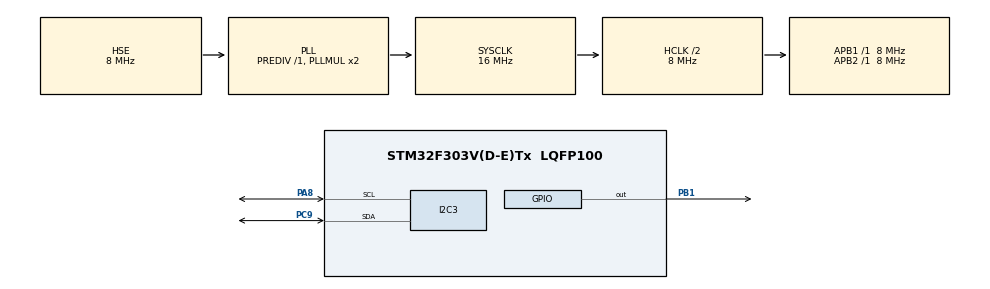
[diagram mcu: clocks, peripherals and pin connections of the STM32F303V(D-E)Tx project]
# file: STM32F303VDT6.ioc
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Mcu.Family=STM32F3
Mcu.Name=STM32F303V(D-E)Tx
Mcu.Package=LQFP100
NVIC.PriorityGroup=NVIC_PRIORITYGROUP_4
NVIC.TIM6_DAC_IRQn=true\:0\:0\:false\:false\:true\:true
NVIC.TIM7_IRQn=true\:0\:0\:false\:false\:true\:true
PA8.Mode=I2C
PA8.Signal=I2C3_SCL
PB1.Signal=GPIO_Output
PC9.Mode=I2C
PC9.Signal=I2C3_SDA
PF0-OSC_IN.Mode=HSE-External-Oscillator
PF0-OSC_IN.Signal=RCC_OSC_IN
PF1-OSC_OUT.Mode=HSE-External-Oscillator
PF1-OSC_OUT.Signal=RCC_OSC_OUT
ProjectManager.HeapSize=0x200
ProjectManager.StackSize=0x400
ProjectManager.TargetToolchain=TrueSTUDIO
RCC.AHBCLKDivider=RCC_SYSCLK_DIV2
RCC.AHBFreq_Value=8000000
RCC.APB1Freq_Value=8000000
RCC.APB1TimFreq_Value=8000000
RCC.APB2Freq_Value=8000000
RCC.APB2TimFreq_Value=8000000
RCC.CortexFreq_Value=8000000
RCC.HCLKFreq_Value=8000000
RCC.HSE_VALUE=8000000
RCC.HSI_VALUE=8000000
RCC.PLLSourceVirtual=RCC_PLLSOURCE_HSE
RCC.SYSCLKFreq_VALUE=16000000
RCC.SYSCLKSourceVirtual=RCC_SYSCLKSOURCE_PLLCLK
RCC.USBFreq_Value=16000000
TIM6.Period=500
TIM6.Prescaler=8000
TIM6.TIM_MasterOutputTrigger=TIM_TRGO_UPDATE
TIM7.Period=2000
TIM7.Prescaler=8000
VP_TIM6_VS_ClockSourceINT.Mode=Enable_Timer
VP_TIM7_VS_ClockSourceINT.Mode=Enable_Timer
board=STM32F303VDT6

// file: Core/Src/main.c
/**
  ******************************************************************************
  * @file           : main.c
  * @brief          : Main program body
  ******************************************************************************
  ** This notice applies to any and all portions of this file
  * that are not between comment pairs USER CODE BEGIN and
  * USER CODE END. Other portions of this file, whether
  * inserted by the user or by software development tools
  * are owned by their respective copyright owners.
  *
  * COPYRIGHT(c) 2018 STMicroelectronics
  *
  * Redistribution and use in source and binary forms, with or without modification,
  * are permitted provided that the following conditions are met:
  *   1. Redistributions of source code must retain the above copyright notice,
  *      this list of conditions and the following disclaimer.
  *   2. Redistributions in binary form must reproduce the above copyright notice,
  *      this list of conditions and the following disclaimer in the documentation
  *      and/or other materials provided with the distribution.
  *   3. Neither the name of STMicroelectronics nor the names of its contributors
  *      may be used to endorse or promote products derived from this software
  *      without specific prior written permission.
  *
  * THIS SOFTWARE IS PROVIDED BY THE COPYRIGHT HOLDERS AND CONTRIBUTORS "AS IS"
  * AND ANY EXPRESS OR IMPLIED WARRANTIES, INCLUDING, BUT NOT LIMITED TO, THE
  * IMPLIED WARRANTIES OF MERCHANTABILITY AND FITNESS FOR A PARTICULAR PURPOSE ARE
  * DISCLAIMED. IN NO EVENT SHALL THE COPYRIGHT HOLDER OR CONTRIBUTORS BE LIABLE
  * FOR ANY DIRECT, INDIRECT, INCIDENTAL, SPECIAL, EXEMPLARY, OR CONSEQUENTIAL
  * DAMAGES (INCLUDING, BUT NOT LIMITED TO, PROCUREMENT OF SUBSTITUTE GOODS OR
  * SERVICES; LOSS OF USE, DATA, OR PROFITS; OR BUSINESS INTERRUPTION) HOWEVER
  * CAUSED AND ON ANY THEORY OF LIABILITY, WHETHER IN CONTRACT, STRICT LIABILITY,
  * OR TORT (INCLUDING NEGLIGENCE OR OTHERWISE) ARISING IN ANY WAY OUT OF THE USE
  * OF THIS SOFTWARE, EVEN IF ADVISED OF THE POSSIBILITY OF SUCH DAMAGE.
  *
  ******************************************************************************
  */
#include "main.h"
#include "stm32f3xx_hal.h"

I2C_HandleTypeDef hi2c3;

TIM_HandleTypeDef htim6;
TIM_HandleTypeDef htim7;

/* USER CODE BEGIN PV */
/* Private variables ---------------------------------------------------------*/

/* USER CODE END PV */

void SystemClock_Config(void);
static void MX_GPIO_Init(void);
static void MX_TIM6_Init(void);
static void MX_TIM7_Init(void);
static void MX_I2C3_Init(void);

/* USER CODE BEGIN PFP */
/* Private function prototypes -----------------------------------------------*/

/* USER CODE END PFP */

/* USER CODE BEGIN 0 */
void OwnInit(void);
void Timer6(void);
void Timer7(void);
void I2C_Send(int adress,uint8_t buffer[8]);
//*********************************************************************ГЛОБАЛЬНЫЕ ПЕРЕМЕННЫЕ*******************************************************
volatile uint8_t monitor = 0;
volatile uint8_t value;
uint8_t str2[]="SET\r\n";
volatile uint8_t i2c_mon = 0;
/* USER CODE END 0 */

int main(void)
{

  /* MCU Configuration----------------------------------------------------------*/

  /* Reset of all peripherals, Initializes the Flash interface and the Systick. */
  HAL_Init();

  /* Configure the system clock */
  SystemClock_Config();

  /* Initialize all configured peripherals */
  MX_GPIO_Init();
  MX_TIM6_Init();
  MX_TIM7_Init();
  MX_I2C3_Init();

  /* Infinite loop */
  /* USER CODE BEGIN WHILE */
  //HAL_UART_Receive(&huart2, strRX, 8, 0xFFFF);

  OwnInit();

  while (1)
  {
	  /*HAL_Delay(100);
	  HAL_UART_Receive(&huart2, strRX, 8, 0xFFFF);
	  //HAL_UART_Receive(&huart2, strRX, 8, 0xFFFF);
	  if(huart2.RxXferCount == 0)
	  {
		  HAL_UART_Transmit(&huart2, strRX, 8, 0xFFFF);
	  }*/

	  //HAL_UART_Transmit(&huart2, str, 16, 0xFFFF);
	  //HAL_Delay(1000);
  /* USER CODE END WHILE */

  }

}

void SystemClock_Config(void)
{

  RCC_OscInitTypeDef RCC_OscInitStruct;
  RCC_ClkInitTypeDef RCC_ClkInitStruct;
  RCC_PeriphCLKInitTypeDef PeriphClkInit;

    /**Initializes the CPU, AHB and APB busses clocks
    */
  RCC_OscInitStruct.OscillatorType = RCC_OSCILLATORTYPE_HSI|RCC_OSCILLATORTYPE_HSE;
  RCC_OscInitStruct.HSEState = RCC_HSE_ON;
  RCC_OscInitStruct.HSIState = RCC_HSI_ON;
  RCC_OscInitStruct.HSICalibrationValue = 16;
  RCC_OscInitStruct.PLL.PLLState = RCC_PLL_ON;
  RCC_OscInitStruct.PLL.PLLSource = RCC_PLLSOURCE_HSE;
  RCC_OscInitStruct.PLL.PLLMUL = RCC_PLL_MUL2;
  RCC_OscInitStruct.PLL.PREDIV = RCC_PREDIV_DIV1;
  if (HAL_RCC_OscConfig(&RCC_OscInitStruct) != HAL_OK)
  {
    _Error_Handler(__FILE__, __LINE__);
  }

    /**Initializes the CPU, AHB and APB busses clocks
    */
  RCC_ClkInitStruct.ClockType = RCC_CLOCKTYPE_HCLK|RCC_CLOCKTYPE_SYSCLK
                              |RCC_CLOCKTYPE_PCLK1|RCC_CLOCKTYPE_PCLK2;
  RCC_ClkInitStruct.SYSCLKSource = RCC_SYSCLKSOURCE_PLLCLK;
  RCC_ClkInitStruct.AHBCLKDivider = RCC_SYSCLK_DIV2;
  RCC_ClkInitStruct.APB1CLKDivider = RCC_HCLK_DIV1;
  RCC_ClkInitStruct.APB2CLKDivider = RCC_HCLK_DIV1;

  if (HAL_RCC_ClockConfig(&RCC_ClkInitStruct, FLASH_LATENCY_0) != HAL_OK)
  {
    _Error_Handler(__FILE__, __LINE__);
  }

  PeriphClkInit.PeriphClockSelection = RCC_PERIPHCLK_I2C3;
  PeriphClkInit.I2c3ClockSelection = RCC_I2C3CLKSOURCE_HSI;
  if (HAL_RCCEx_PeriphCLKConfig(&PeriphClkInit) != HAL_OK)
  {
    _Error_Handler(__FILE__, __LINE__);
  }

    /**Configure the Systick interrupt time
    */
  HAL_SYSTICK_Config(HAL_RCC_GetHCLKFreq()/1000);

    /**Configure the Systick
    */
  HAL_SYSTICK_CLKSourceConfig(SYSTICK_CLKSOURCE_HCLK);

  /* SysTick_IRQn interrupt configuration */
  HAL_NVIC_SetPriority(SysTick_IRQn, 0, 0);
}

/* I2C3 init function */
static void MX_I2C3_Init(void)
{

  hi2c3.Instance = I2C3;
  hi2c3.Init.Timing = 0x2000090E;
  hi2c3.Init.OwnAddress1 = 0;
  hi2c3.Init.AddressingMode = I2C_ADDRESSINGMODE_7BIT;
  hi2c3.Init.DualAddressMode = I2C_DUALADDRESS_DISABLE;
  hi2c3.Init.OwnAddress2 = 0;
  hi2c3.Init.OwnAddress2Masks = I2C_OA2_NOMASK;
  hi2c3.Init.GeneralCallMode = I2C_GENERALCALL_DISABLE;
  hi2c3.Init.NoStretchMode = I2C_NOSTRETCH_DISABLE;
  if (HAL_I2C_Init(&hi2c3) != HAL_OK)
  {
    _Error_Handler(__FILE__, __LINE__);
  }

    /**Configure Analogue filter
    */
  if (HAL_I2CEx_ConfigAnalogFilter(&hi2c3, I2C_ANALOGFILTER_ENABLE) != HAL_OK)
  {
    _Error_Handler(__FILE__, __LINE__);
  }

    /**Configure Digital filter
    */
  if (HAL_I2CEx_ConfigDigitalFilter(&hi2c3, 0) != HAL_OK)
  {
    _Error_Handler(__FILE__, __LINE__);
  }

}

/* TIM6 init function */
static void MX_TIM6_Init(void)
{

  TIM_MasterConfigTypeDef sMasterConfig;

  htim6.Instance = TIM6;
  htim6.Init.Prescaler = 8000;
  htim6.Init.CounterMode = TIM_COUNTERMODE_UP;
  htim6.Init.Period = 500;
  htim6.Init.AutoReloadPreload = TIM_AUTORELOAD_PRELOAD_DISABLE;
  if (HAL_TIM_Base_Init(&htim6) != HAL_OK)
  {
    _Error_Handler(__FILE__, __LINE__);
  }

  sMasterConfig.MasterOutputTrigger = TIM_TRGO_UPDATE;
  sMasterConfig.MasterSlaveMode = TIM_MASTERSLAVEMODE_DISABLE;
  if (HAL_TIMEx_MasterConfigSynchronization(&htim6, &sMasterConfig) != HAL_OK)
  {
    _Error_Handler(__FILE__, __LINE__);
  }

}

/* TIM7 init function */
static void MX_TIM7_Init(void)
{

  TIM_MasterConfigTypeDef sMasterConfig;

  htim7.Instance = TIM7;
  htim7.Init.Prescaler = 8000;
  htim7.Init.CounterMode = TIM_COUNTERMODE_UP;
  htim7.Init.Period = 2000;
  htim7.Init.AutoReloadPreload = TIM_AUTORELOAD_PRELOAD_DISABLE;
  if (HAL_TIM_Base_Init(&htim7) != HAL_OK)
  {
    _Error_Handler(__FILE__, __LINE__);
  }

  sMasterConfig.MasterOutputTrigger = TIM_TRGO_RESET;
  sMasterConfig.MasterSlaveMode = TIM_MASTERSLAVEMODE_DISABLE;
  if (HAL_TIMEx_MasterConfigSynchronization(&htim7, &sMasterConfig) != HAL_OK)
  {
    _Error_Handler(__FILE__, __LINE__);
  }

}

/** Configure pins as
        * Analog
        * Input
        * Output
        * EVENT_OUT
        * EXTI
*/
static void MX_GPIO_Init(void)
{

  GPIO_InitTypeDef GPIO_InitStruct;

  /* GPIO Ports Clock Enable */
  __HAL_RCC_GPIOF_CLK_ENABLE();
  __HAL_RCC_GPIOB_CLK_ENABLE();
  __HAL_RCC_GPIOC_CLK_ENABLE();
  __HAL_RCC_GPIOA_CLK_ENABLE();

  /*Configure GPIO pin Output Level */
  HAL_GPIO_WritePin(GPIOB, GPIO_PIN_1, GPIO_PIN_RESET);

  /*Configure GPIO pin : PB1 */
  GPIO_InitStruct.Pin = GPIO_PIN_1;
  GPIO_InitStruct.Mode = GPIO_MODE_OUTPUT_PP;
  GPIO_InitStruct.Pull = GPIO_NOPULL;
  GPIO_InitStruct.Speed = GPIO_SPEED_FREQ_LOW;
  HAL_GPIO_Init(GPIOB, &GPIO_InitStruct);

}

/* USER CODE BEGIN 4 */
void OwnInit(void)
{
	HAL_TIM_Base_Start(&htim6);
	HAL_TIM_Base_Start_IT(&htim6);
	HAL_TIM_Base_Start(&htim7);
	HAL_TIM_Base_Start_IT(&htim7);

}

void Timer6(void)
{

	HAL_GPIO_TogglePin(GPIOB, GPIO_PIN_1);
	/*if(HAL_GPIO_ReadPin(GPIOD, GPIO_PIN_1) == GPIO_PIN_SET)
	{
		HAL_UART_Transmit(&huart2, str2, 4, 0xFFFF);
	}*/
	monitor++;
	value = monitor;
}

void I2C_Send(int adress,uint8_t buffer[3])
{

	HAL_I2C_Master_Transmit(&hi2c3,adress << 1, buffer, 3, 100);
}

void Timer7(void)
{
	uint8_t mail[3] = {0xFF, 0xAA, 0x02};
	I2C_Send(0b110100, mail);
	i2c_mon++;
}
/* USER CODE END 4 */

void _Error_Handler(char *file, int line)
{
  while(1)
  {
  }
}

/************************ (C) COPYRIGHT STMicroelectronics *****END OF FILE****/
